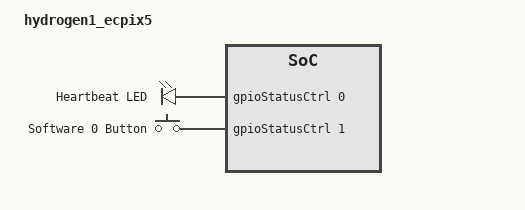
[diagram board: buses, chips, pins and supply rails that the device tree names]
/dts-v1/;
#include <hydrogen/hydrogen1.dtsi>

/ {
	model = "hydrogen1_ecpix5";
	compatible = "elements,hydrogen1_ecpix5";

	chosen {
		zephyr,console = &uartStdCtrl;
		zephyr,shell-uart = &uartStdCtrl;
		zephyr,sram = &ram0;
	};
	leds {
		compatible = "gpio-leds";
		heartbeat: HEARTBEAT {
			gpios = <&gpioStatusCtrl 0 GPIO_ACTIVE_HIGH>;
			label = "Heartbeat LED";
		};
	};
	keys {
		compatible = "gpio-keys";
		sw0: SW0 {
			gpios = <&gpioStatusCtrl 1 GPIO_ACTIVE_HIGH>;
			label = "Software 0 Button";
		};
	};
};

&uartStdCtrl {
	clock-frequency = <100000000>;
};
